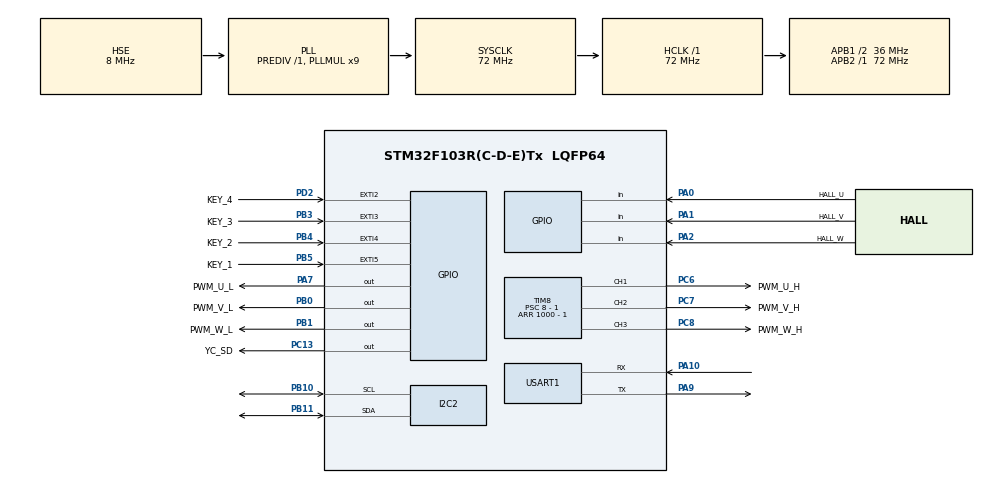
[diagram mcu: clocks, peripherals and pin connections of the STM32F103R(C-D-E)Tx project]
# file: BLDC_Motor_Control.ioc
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Mcu.Family=STM32F1
Mcu.Name=STM32F103R(C-D-E)Tx
Mcu.Package=LQFP64
NVIC.EXTI2_IRQn=true\:5\:0\:true\:false\:true\:true\:true\:true
NVIC.EXTI3_IRQn=true\:5\:0\:true\:false\:true\:true\:true\:true
NVIC.EXTI4_IRQn=true\:5\:0\:true\:false\:true\:true\:true\:true
NVIC.EXTI9_5_IRQn=true\:5\:0\:true\:false\:true\:true\:true\:true
NVIC.PriorityGroup=NVIC_PRIORITYGROUP_4
NVIC.TIM8_UP_IRQn=true\:2\:0\:true\:false\:true\:true\:true\:true
PA0-WKUP.GPIO_Label=HALL_U
PA0-WKUP.Signal=GPIO_Input
PA1.GPIO_Label=HALL_V
PA1.Signal=GPIO_Input
PA10.Mode=Asynchronous
PA10.Signal=USART1_RX
PA13.Mode=Serial_Wire
PA13.Signal=SYS_JTMS-SWDIO
PA14.Mode=Serial_Wire
PA14.Signal=SYS_JTCK-SWCLK
PA2.GPIO_Label=HALL_W
PA2.Signal=GPIO_Input
PA7.GPIO_Label=PWM_U_L
PA7.GPIO_ModeDefaultOutputPP=GPIO_MODE_OUTPUT_PP
PA7.GPIO_PuPd=GPIO_NOPULL
PA7.GPIO_Speed=GPIO_SPEED_FREQ_HIGH
PA7.PinState=GPIO_PIN_RESET
PA7.Signal=GPIO_Output
PA9.Mode=Asynchronous
PA9.Signal=USART1_TX
PB0.GPIO_Label=PWM_V_L
PB0.GPIO_ModeDefaultOutputPP=GPIO_MODE_OUTPUT_PP
PB0.GPIO_PuPd=GPIO_NOPULL
PB0.GPIO_Speed=GPIO_SPEED_FREQ_HIGH
PB0.PinState=GPIO_PIN_RESET
PB0.Signal=GPIO_Output
PB1.GPIO_Label=PWM_W_L
PB1.GPIO_ModeDefaultOutputPP=GPIO_MODE_OUTPUT_PP
PB1.GPIO_PuPd=GPIO_NOPULL
PB1.GPIO_Speed=GPIO_SPEED_FREQ_HIGH
PB1.PinState=GPIO_PIN_RESET
PB1.Signal=GPIO_Output
PB10.Mode=I2C
PB10.Signal=I2C2_SCL
PB11.Mode=I2C
PB11.Signal=I2C2_SDA
PB3.GPIO_Label=KEY_3
PB3.GPIO_ModeDefaultEXTI=GPIO_MODE_IT_FALLING
PB3.GPIO_PuPd=GPIO_PULLUP
PB3.Signal=GPXTI3
PB4.GPIO_Label=KEY_2
PB4.GPIO_ModeDefaultEXTI=GPIO_MODE_IT_FALLING
PB4.GPIO_PuPd=GPIO_PULLUP
PB4.Signal=GPXTI4
PB5.GPIO_Label=KEY_1
PB5.GPIO_ModeDefaultEXTI=GPIO_MODE_IT_FALLING
PB5.GPIO_PuPd=GPIO_PULLUP
PB5.Signal=GPXTI5
PC13-TAMPER-RTC.GPIO_Label=YC_SD
PC13-TAMPER-RTC.GPIO_Speed=GPIO_SPEED_FREQ_HIGH
PC13-TAMPER-RTC.PinState=GPIO_PIN_RESET
PC13-TAMPER-RTC.Signal=GPIO_Output
PC14-OSC32_IN.Mode=LSE-External-Oscillator
PC14-OSC32_IN.Signal=RCC_OSC32_IN
PC15-OSC32_OUT.Mode=LSE-External-Oscillator
PC15-OSC32_OUT.Signal=RCC_OSC32_OUT
PC6.GPIO_Label=PWM_U_H
PC6.Signal=S_TIM8_CH1
PC7.GPIO_Label=PWM_V_H
PC7.Signal=S_TIM8_CH2
PC8.GPIO_Label=PWM_W_H
PC8.Signal=S_TIM8_CH3
PD0-OSC_IN.Mode=HSE-External-Oscillator
PD0-OSC_IN.Signal=RCC_OSC_IN
PD1-OSC_OUT.Mode=HSE-External-Oscillator
PD1-OSC_OUT.Signal=RCC_OSC_OUT
PD2.GPIO_Label=KEY_4
PD2.GPIO_ModeDefaultEXTI=GPIO_MODE_IT_FALLING
PD2.GPIO_PuPd=GPIO_PULLUP
PD2.Signal=GPXTI2
ProjectManager.HeapSize=0x200
ProjectManager.StackSize=0x400
ProjectManager.TargetToolchain=MDK-ARM V5.32
RCC.AHBFreq_Value=72000000
RCC.APB1CLKDivider=RCC_HCLK_DIV2
RCC.APB1Freq_Value=36000000
RCC.APB1TimFreq_Value=72000000
RCC.APB2Freq_Value=72000000
RCC.APB2TimFreq_Value=72000000
RCC.HCLKFreq_Value=72000000
RCC.PLLMUL=RCC_PLL_MUL9
RCC.PLLSourceVirtual=RCC_PLLSOURCE_HSE
RCC.SYSCLKFreq_VALUE=72000000
RCC.SYSCLKSource=RCC_SYSCLKSOURCE_PLLCLK
RCC.USBFreq_Value=72000000
SH.S_TIM8_CH1.0=TIM8_CH1,PWM Generation1 CH1
SH.S_TIM8_CH2.0=TIM8_CH2,PWM Generation2 CH2
SH.S_TIM8_CH3.0=TIM8_CH3,PWM Generation3 CH3
TIM8.Channel-PWM\ Generation1\ CH1=TIM_CHANNEL_1
TIM8.Channel-PWM\ Generation2\ CH2=TIM_CHANNEL_2
TIM8.Channel-PWM\ Generation3\ CH3=TIM_CHANNEL_3
TIM8.Period=1000 - 1
TIM8.Prescaler=8 - 1
USART1.VirtualMode=VM_ASYNC
VP_TIM8_VS_ClockSourceINT.Mode=Internal
board=custom

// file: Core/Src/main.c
/* USER CODE BEGIN Header */
/**
 ******************************************************************************
 * @file           : main.c
 * @brief          : Main program body
 ******************************************************************************
 * @attention
 *
 * Copyright (c) 2025 STMicroelectronics.
 * All rights reserved.
 *
 * This software is licensed under terms that can be found in the LICENSE file
 * in the root directory of this software component.
 * If no LICENSE file comes with this software, it is provided AS-IS.
 *
 ******************************************************************************
 */
/* USER CODE END Header */
#include "main.h"
#include "i2c.h"
#include "tim.h"
#include "usart.h"
#include "gpio.h"

/* USER CODE BEGIN Includes */
#include "App_Display.h"
#include "App_Key.h"
#include "Com_Debug.h"
#include "Int_oled.h"
#include "Int_EEPROM.h"
#include "Int_BLDC.h"

/* USER CODE END Includes */

void SystemClock_Config(void);

int main(void)
{

    /* MCU Configuration--------------------------------------------------------*/

    /* Reset of all peripherals, Initializes the Flash interface and the Systick. */
    HAL_Init();

    /* Configure the system clock */
    SystemClock_Config();

    /* Initialize all configured peripherals */
    MX_GPIO_Init();
    MX_USART1_UART_Init();
    MX_I2C2_Init();
    MX_TIM8_Init();
    /* USER CODE BEGIN 2 */
    Debug_printf("hello\r\n");
    App_Display_Init();
    App_Motor_ID_Init();
    extern int16_t set_motor_speed;

    /* USER CODE END 2 */

    /* Infinite loop */
    /* USER CODE BEGIN WHILE */
    while (1)
    {
        App_Key_Process();
        App_Display_Show();

        /* USER CODE END WHILE */

    }
}

void SystemClock_Config(void)
{
    RCC_OscInitTypeDef RCC_OscInitStruct = {0};
    RCC_ClkInitTypeDef RCC_ClkInitStruct = {0};

    /** Initializes the RCC Oscillators according to the specified parameters
     * in the RCC_OscInitTypeDef structure.
     */
    RCC_OscInitStruct.OscillatorType = RCC_OSCILLATORTYPE_HSE;
    RCC_OscInitStruct.HSEState       = RCC_HSE_ON;
    RCC_OscInitStruct.HSEPredivValue = RCC_HSE_PREDIV_DIV1;
    RCC_OscInitStruct.HSIState       = RCC_HSI_ON;
    RCC_OscInitStruct.PLL.PLLState   = RCC_PLL_ON;
    RCC_OscInitStruct.PLL.PLLSource  = RCC_PLLSOURCE_HSE;
    RCC_OscInitStruct.PLL.PLLMUL     = RCC_PLL_MUL9;
    if (HAL_RCC_OscConfig(&RCC_OscInitStruct) != HAL_OK)
    {
        Error_Handler();
    }

    /** Initializes the CPU, AHB and APB buses clocks
     */
    RCC_ClkInitStruct.ClockType      = RCC_CLOCKTYPE_HCLK | RCC_CLOCKTYPE_SYSCLK | RCC_CLOCKTYPE_PCLK1 | RCC_CLOCKTYPE_PCLK2;
    RCC_ClkInitStruct.SYSCLKSource   = RCC_SYSCLKSOURCE_PLLCLK;
    RCC_ClkInitStruct.AHBCLKDivider  = RCC_SYSCLK_DIV1;
    RCC_ClkInitStruct.APB1CLKDivider = RCC_HCLK_DIV2;
    RCC_ClkInitStruct.APB2CLKDivider = RCC_HCLK_DIV1;

    if (HAL_RCC_ClockConfig(&RCC_ClkInitStruct, FLASH_LATENCY_2) != HAL_OK)
    {
        Error_Handler();
    }
}

void Error_Handler(void)
{
    __disable_irq();
    while (1)
    {
    }
}
